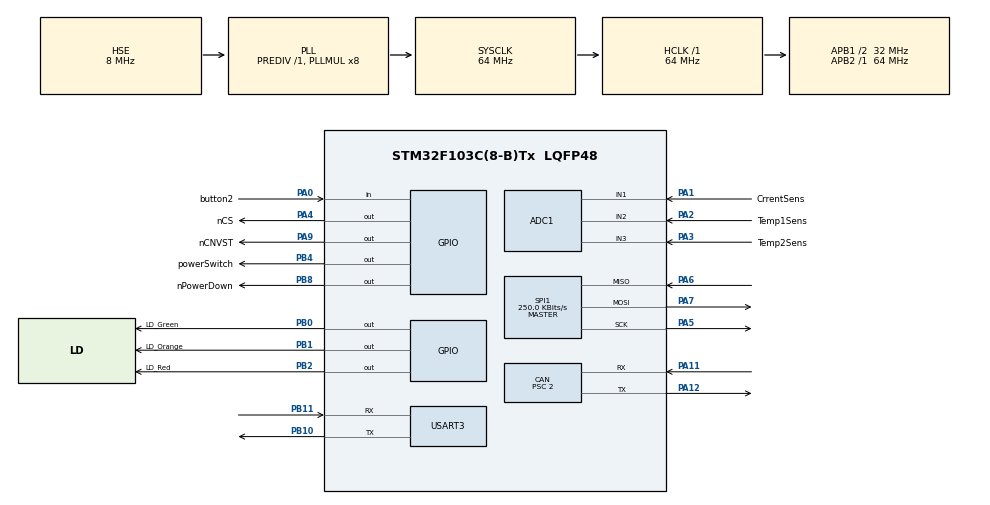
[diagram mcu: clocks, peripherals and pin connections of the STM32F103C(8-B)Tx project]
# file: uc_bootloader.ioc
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ADC1.Channel-0\#ChannelRegularConversion=ADC_CHANNEL_1
ADC1.Channel-1\#ChannelRegularConversion=ADC_CHANNEL_2
ADC1.Channel-2\#ChannelRegularConversion=ADC_CHANNEL_3
ADC1.ContinuousConvMode=DISABLE
ADC1.ExternalTrigConv=ADC_EXTERNALTRIGCONV_T3_TRGO
ADC1.NbrOfConversion=3
ADC1.NbrOfConversionFlag=1
ADC1.Rank-0\#ChannelRegularConversion=1
ADC1.Rank-1\#ChannelRegularConversion=2
ADC1.Rank-2\#ChannelRegularConversion=3
ADC1.SamplingTime-0\#ChannelRegularConversion=ADC_SAMPLETIME_71CYCLES_5
ADC1.SamplingTime-1\#ChannelRegularConversion=ADC_SAMPLETIME_71CYCLES_5
ADC1.SamplingTime-2\#ChannelRegularConversion=ADC_SAMPLETIME_71CYCLES_5
ADC1.master=1
CAN.BS1=CAN_BS1_13TQ
CAN.BS2=CAN_BS2_2TQ
CAN.CalculateBaudRate=1000000
CAN.CalculateTimeBit=1000.00
CAN.CalculateTimeQuantum=62.5
CAN.Prescaler=2
Dma.ADC1.2.Direction=DMA_PERIPH_TO_MEMORY
Dma.ADC1.2.Instance=DMA1_Channel1
Dma.ADC1.2.MemDataAlignment=DMA_MDATAALIGN_HALFWORD
Dma.ADC1.2.MemInc=DMA_MINC_ENABLE
Dma.ADC1.2.Mode=DMA_CIRCULAR
Dma.ADC1.2.PeriphDataAlignment=DMA_PDATAALIGN_HALFWORD
Dma.ADC1.2.PeriphInc=DMA_PINC_DISABLE
Dma.ADC1.2.Priority=DMA_PRIORITY_LOW
Dma.Request0=SPI1_RX
Dma.Request1=SPI1_TX
Dma.Request2=ADC1
Dma.SPI1_RX.0.Direction=DMA_PERIPH_TO_MEMORY
Dma.SPI1_RX.0.Instance=DMA1_Channel2
Dma.SPI1_RX.0.MemDataAlignment=DMA_MDATAALIGN_BYTE
Dma.SPI1_RX.0.MemInc=DMA_MINC_ENABLE
Dma.SPI1_RX.0.Mode=DMA_NORMAL
Dma.SPI1_RX.0.PeriphDataAlignment=DMA_PDATAALIGN_BYTE
Dma.SPI1_RX.0.PeriphInc=DMA_PINC_DISABLE
Dma.SPI1_RX.0.Priority=DMA_PRIORITY_HIGH
Dma.SPI1_TX.1.Direction=DMA_MEMORY_TO_PERIPH
Dma.SPI1_TX.1.Instance=DMA1_Channel3
Dma.SPI1_TX.1.MemDataAlignment=DMA_MDATAALIGN_BYTE
Dma.SPI1_TX.1.MemInc=DMA_MINC_ENABLE
Dma.SPI1_TX.1.Mode=DMA_NORMAL
Dma.SPI1_TX.1.PeriphDataAlignment=DMA_PDATAALIGN_BYTE
Dma.SPI1_TX.1.PeriphInc=DMA_PINC_DISABLE
Dma.SPI1_TX.1.Priority=DMA_PRIORITY_HIGH
Mcu.Family=STM32F1
Mcu.Name=STM32F103C(8-B)Tx
Mcu.Package=LQFP48
NVIC.DMA1_Channel1_IRQn=true\:2\:1\:true\:false\:true\:false\:true
NVIC.DMA1_Channel2_IRQn=true\:2\:0\:true\:false\:true\:false\:true
NVIC.DMA1_Channel3_IRQn=true\:2\:0\:true\:false\:true\:false\:true
NVIC.PriorityGroup=NVIC_PRIORITYGROUP_3
NVIC.TIM1_BRK_IRQn=true\:3\:1\:true\:false\:true\:true\:true
NVIC.TIM1_UP_IRQn=true\:3\:1\:true\:false\:true\:true\:true
NVIC.TIM2_IRQn=true\:1\:0\:true\:false\:true\:true\:true
NVIC.TIM4_IRQn=true\:3\:0\:true\:false\:true\:true\:true
NVIC.USB_HP_CAN1_TX_IRQn=true\:1\:0\:true\:false\:true\:true\:true
NVIC.USB_LP_CAN1_RX0_IRQn=true\:1\:0\:true\:false\:true\:true\:true
PA0-WKUP.GPIO_Label=button2
PA0-WKUP.Signal=GPIO_Input
PA1.GPIO_Label=CrrentSens
PA1.Signal=ADCx_IN1
PA11.Mode=CAN_Activate
PA11.Signal=CAN_RX
PA12.Mode=CAN_Activate
PA12.Signal=CAN_TX
PA13.Mode=Serial_Wire
PA13.Signal=SYS_JTMS-SWDIO
PA14.Mode=Serial_Wire
PA14.Signal=SYS_JTCK-SWCLK
PA2.GPIO_Label=Temp1Sens
PA2.Signal=ADCx_IN2
PA3.GPIO_Label=Temp2Sens
PA3.Signal=ADCx_IN3
PA4.GPIO_Label=nCS
PA4.GPIO_Speed=GPIO_SPEED_FREQ_HIGH
PA4.Signal=GPIO_Output
PA5.Mode=Full_Duplex_Master
PA5.Signal=SPI1_SCK
PA6.Mode=Full_Duplex_Master
PA6.Signal=SPI1_MISO
PA7.Mode=Full_Duplex_Master
PA7.Signal=SPI1_MOSI
PA9.GPIO_Label=nCNVST
PA9.GPIO_Speed=GPIO_SPEED_FREQ_HIGH
PA9.Signal=GPIO_Output
PB0.GPIO_Label=LD_Green
PB0.PinState=GPIO_PIN_RESET
PB0.Signal=GPIO_Output
PB1.GPIO_Label=LD_Orange
PB1.Signal=GPIO_Output
PB10.Mode=Asynchronous
PB10.Signal=USART3_TX
PB11.Mode=Asynchronous
PB11.Signal=USART3_RX
PB2.GPIO_Label=LD_Red
PB2.Signal=GPIO_Output
PB4.GPIO_Label=powerSwitch
PB4.GPIO_Speed=GPIO_SPEED_FREQ_MEDIUM
PB4.Signal=GPIO_Output
PB8.GPIO_Label=nPowerDown
PB8.GPIO_Speed=GPIO_SPEED_FREQ_MEDIUM
PB8.Signal=GPIO_Output
PD0-OSC_IN.Mode=HSE-External-Oscillator
PD0-OSC_IN.Signal=RCC_OSC_IN
PD1-OSC_OUT.Mode=HSE-External-Oscillator
PD1-OSC_OUT.Signal=RCC_OSC_OUT
ProjectManager.HeapSize=0x200
ProjectManager.StackSize=0x400
ProjectManager.TargetToolchain=STM32CubeIDE
RCC.ADCPresc=RCC_ADCPCLK2_DIV8
RCC.AHBFreq_Value=64000000
RCC.APB1CLKDivider=RCC_HCLK_DIV2
RCC.APB1Freq_Value=32000000
RCC.APB1TimFreq_Value=64000000
RCC.APB2Freq_Value=64000000
RCC.APB2TimFreq_Value=64000000
RCC.HCLKFreq_Value=64000000
RCC.PLLMUL=RCC_PLL_MUL8
RCC.PLLSourceVirtual=RCC_PLLSOURCE_HSE
RCC.SYSCLKFreq_VALUE=64000000
RCC.SYSCLKSource=RCC_SYSCLKSOURCE_PLLCLK
RCC.USBFreq_Value=64000000
SH.ADCx_IN1.0=ADC1_IN1,IN1
SH.ADCx_IN2.0=ADC1_IN2,IN2
SH.ADCx_IN3.0=ADC1_IN3,IN3
SPI1.BaudRatePrescaler=SPI_BAUDRATEPRESCALER_256
SPI1.CLKPhase=SPI_PHASE_2EDGE
SPI1.CalculateBaudRate=250.0 KBits/s
SPI1.Direction=SPI_DIRECTION_2LINES
SPI1.Mode=SPI_MODE_MASTER
SPI1.VirtualType=VM_MASTER
TIM1.Period=30
TIM1.Prescaler=63999
TIM2.Period=100
TIM2.Prescaler=63999
TIM3.Period=10
TIM3.Prescaler=63999
TIM3.TIM_MasterOutputTrigger=TIM_TRGO_UPDATE
TIM4.Period=60
TIM4.Prescaler=63999
USART3.VirtualMode=VM_ASYNC
VP_TIM1_VS_ClockSourceINT.Mode=Internal
VP_TIM2_VS_ClockSourceINT.Mode=Internal
VP_TIM3_VS_ClockSourceINT.Mode=Internal
VP_TIM4_VS_ClockSourceINT.Mode=Internal
board=custom

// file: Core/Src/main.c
/* USER CODE BEGIN Header */
/**
  ******************************************************************************
  * @file           : main.c
  * @brief          : Main program body
  ******************************************************************************
  * @attention
  *
  * <h2><center>&copy; Copyright (c) 2021 STMicroelectronics.
  * All rights reserved.</center></h2>
  *
  * This software component is licensed by ST under BSD 3-Clause license,
  * the "License"; You may not use this file except in compliance with the
  * License. You may obtain a copy of the License at:
  *                        opensource.org/licenses/BSD-3-Clause
  *
  ******************************************************************************
  */
/* USER CODE END Header */
#include "main.h"
#include "boot_ctrl.h"
#include "can.h"
#include "flash_memory.h"
#include "timers.h"

ADC_HandleTypeDef hadc1;
DMA_HandleTypeDef hdma_adc1;

CAN_HandleTypeDef hcan;

SPI_HandleTypeDef hspi1;
DMA_HandleTypeDef hdma_spi1_rx;
DMA_HandleTypeDef hdma_spi1_tx;

TIM_HandleTypeDef htim1;
TIM_HandleTypeDef htim2;
TIM_HandleTypeDef htim3;
TIM_HandleTypeDef htim4;

UART_HandleTypeDef huart3;

void SystemClock_Config(void);
static void MX_GPIO_Init(void);
static void MX_DMA_Init(void);
static void MX_ADC1_Init(void);
static void MX_CAN_Init(void);
static void MX_SPI1_Init(void);
static void MX_TIM1_Init(void);
static void MX_TIM2_Init(void);
static void MX_TIM3_Init(void);
static void MX_TIM4_Init(void);
static void MX_USART3_UART_Init(void);

int main(void)
{
	// Flag = 0 --> Jump to App
	// Flag = 1 --> Bootloader Mode
	// Check if app mode is enabled. If yes, jump to app
	if(is_app_mode())
		jump_boot_to_app();

	/* Reset of all peripherals, Initializes the Flash interface and the Systick. */
	HAL_Init();

	/* Configure the system clock */
	SystemClock_Config();

	/* Initialize all configured peripherals */
	MX_GPIO_Init();
	MX_DMA_Init();
	MX_ADC1_Init();
	MX_CAN_Init();
	MX_SPI1_Init();
	MX_TIM1_Init();
	MX_TIM2_Init();
	MX_TIM3_Init();
	MX_TIM4_Init();
	MX_USART3_UART_Init();

	boot_init();

	while (1)
	{
		// CAN bus reception and transmission
		can_core_rx();
		can_core_tx();
		// Bootloader core
		boot_core();
	}
}

void SystemClock_Config(void)
{
  RCC_OscInitTypeDef RCC_OscInitStruct = {0};
  RCC_ClkInitTypeDef RCC_ClkInitStruct = {0};
  RCC_PeriphCLKInitTypeDef PeriphClkInit = {0};

  /** Initializes the RCC Oscillators according to the specified parameters
  * in the RCC_OscInitTypeDef structure.
  */
  RCC_OscInitStruct.OscillatorType = RCC_OSCILLATORTYPE_HSE;
  RCC_OscInitStruct.HSEState = RCC_HSE_ON;
  RCC_OscInitStruct.HSEPredivValue = RCC_HSE_PREDIV_DIV1;
  RCC_OscInitStruct.HSIState = RCC_HSI_ON;
  RCC_OscInitStruct.PLL.PLLState = RCC_PLL_ON;
  RCC_OscInitStruct.PLL.PLLSource = RCC_PLLSOURCE_HSE;
  RCC_OscInitStruct.PLL.PLLMUL = RCC_PLL_MUL8;
  if (HAL_RCC_OscConfig(&RCC_OscInitStruct) != HAL_OK)
  {
    Error_Handler();
  }
  /** Initializes the CPU, AHB and APB buses clocks
  */
  RCC_ClkInitStruct.ClockType = RCC_CLOCKTYPE_HCLK|RCC_CLOCKTYPE_SYSCLK
                              |RCC_CLOCKTYPE_PCLK1|RCC_CLOCKTYPE_PCLK2;
  RCC_ClkInitStruct.SYSCLKSource = RCC_SYSCLKSOURCE_PLLCLK;
  RCC_ClkInitStruct.AHBCLKDivider = RCC_SYSCLK_DIV1;
  RCC_ClkInitStruct.APB1CLKDivider = RCC_HCLK_DIV2;
  RCC_ClkInitStruct.APB2CLKDivider = RCC_HCLK_DIV1;

  if (HAL_RCC_ClockConfig(&RCC_ClkInitStruct, FLASH_LATENCY_2) != HAL_OK)
  {
    Error_Handler();
  }
  PeriphClkInit.PeriphClockSelection = RCC_PERIPHCLK_ADC;
  PeriphClkInit.AdcClockSelection = RCC_ADCPCLK2_DIV8;
  if (HAL_RCCEx_PeriphCLKConfig(&PeriphClkInit) != HAL_OK)
  {
    Error_Handler();
  }
}

static void MX_ADC1_Init(void)
{

  ADC_ChannelConfTypeDef sConfig = {0};

  /** Common config
  */
  hadc1.Instance = ADC1;
  hadc1.Init.ScanConvMode = ADC_SCAN_ENABLE;
  hadc1.Init.ContinuousConvMode = DISABLE;
  hadc1.Init.DiscontinuousConvMode = DISABLE;
  hadc1.Init.ExternalTrigConv = ADC_EXTERNALTRIGCONV_T3_TRGO;
  hadc1.Init.DataAlign = ADC_DATAALIGN_RIGHT;
  hadc1.Init.NbrOfConversion = 3;
  if (HAL_ADC_Init(&hadc1) != HAL_OK)
  {
    Error_Handler();
  }
  /** Configure Regular Channel
  */
  sConfig.Channel = ADC_CHANNEL_1;
  sConfig.Rank = ADC_REGULAR_RANK_1;
  sConfig.SamplingTime = ADC_SAMPLETIME_71CYCLES_5;
  if (HAL_ADC_ConfigChannel(&hadc1, &sConfig) != HAL_OK)
  {
    Error_Handler();
  }
  /** Configure Regular Channel
  */
  sConfig.Channel = ADC_CHANNEL_2;
  sConfig.Rank = ADC_REGULAR_RANK_2;
  if (HAL_ADC_ConfigChannel(&hadc1, &sConfig) != HAL_OK)
  {
    Error_Handler();
  }
  /** Configure Regular Channel
  */
  sConfig.Channel = ADC_CHANNEL_3;
  sConfig.Rank = ADC_REGULAR_RANK_3;
  if (HAL_ADC_ConfigChannel(&hadc1, &sConfig) != HAL_OK)
  {
    Error_Handler();
  }

}

static void MX_CAN_Init(void)
{

  /* USER CODE BEGIN CAN_Init 0 */
//	CAN_FilterTypeDef sFilterConfig_0, sFilterConfig_1, sFilterConfig_2;
  /* USER CODE END CAN_Init 0 */

  hcan.Instance = CAN1;
  hcan.Init.Prescaler = 2;
  hcan.Init.Mode = CAN_MODE_NORMAL;
  hcan.Init.SyncJumpWidth = CAN_SJW_1TQ;
  hcan.Init.TimeSeg1 = CAN_BS1_13TQ;
  hcan.Init.TimeSeg2 = CAN_BS2_2TQ;
  hcan.Init.TimeTriggeredMode = DISABLE;
  hcan.Init.AutoBusOff = DISABLE;
  hcan.Init.AutoWakeUp = DISABLE;
  hcan.Init.AutoRetransmission = DISABLE;
  hcan.Init.ReceiveFifoLocked = DISABLE;
  hcan.Init.TransmitFifoPriority = DISABLE;
  if (HAL_CAN_Init(&hcan) != HAL_OK)
  {
    Error_Handler();
  }
  /* USER CODE BEGIN CAN_Init 2 */
	CAN_FilterTypeDef sf;

	sf.FilterBank = 0;
	sf.FilterMode = CAN_FILTERMODE_IDMASK;
	sf.FilterScale = CAN_FILTERSCALE_32BIT;
	sf.FilterIdLow = 0x600;
	sf.FilterIdHigh = 0x6ff;
	sf.FilterMaskIdLow = 0x0000;
	sf.FilterMaskIdHigh = 0x0000;
	sf.FilterFIFOAssignment = CAN_RX_FIFO0;
	sf.SlaveStartFilterBank = 0;
	sf.FilterActivation = ENABLE;
	if (HAL_CAN_ConfigFilter(&hcan, &sf) != HAL_OK) {
		Error_Handler();
	}
  /* USER CODE END CAN_Init 2 */

}

static void MX_SPI1_Init(void)
{

  /* SPI1 parameter configuration*/
  hspi1.Instance = SPI1;
  hspi1.Init.Mode = SPI_MODE_MASTER;
  hspi1.Init.Direction = SPI_DIRECTION_2LINES;
  hspi1.Init.DataSize = SPI_DATASIZE_8BIT;
  hspi1.Init.CLKPolarity = SPI_POLARITY_LOW;
  hspi1.Init.CLKPhase = SPI_PHASE_2EDGE;
  hspi1.Init.NSS = SPI_NSS_SOFT;
  hspi1.Init.BaudRatePrescaler = SPI_BAUDRATEPRESCALER_256;
  hspi1.Init.FirstBit = SPI_FIRSTBIT_MSB;
  hspi1.Init.TIMode = SPI_TIMODE_DISABLE;
  hspi1.Init.CRCCalculation = SPI_CRCCALCULATION_DISABLE;
  hspi1.Init.CRCPolynomial = 10;
  if (HAL_SPI_Init(&hspi1) != HAL_OK)
  {
    Error_Handler();
  }

}

static void MX_TIM1_Init(void)
{

  TIM_ClockConfigTypeDef sClockSourceConfig = {0};
  TIM_MasterConfigTypeDef sMasterConfig = {0};

  htim1.Instance = TIM1;
  htim1.Init.Prescaler = 63999;
  htim1.Init.CounterMode = TIM_COUNTERMODE_UP;
  htim1.Init.Period = 30;
  htim1.Init.ClockDivision = TIM_CLOCKDIVISION_DIV1;
  htim1.Init.RepetitionCounter = 0;
  htim1.Init.AutoReloadPreload = TIM_AUTORELOAD_PRELOAD_DISABLE;
  if (HAL_TIM_Base_Init(&htim1) != HAL_OK)
  {
    Error_Handler();
  }
  sClockSourceConfig.ClockSource = TIM_CLOCKSOURCE_INTERNAL;
  if (HAL_TIM_ConfigClockSource(&htim1, &sClockSourceConfig) != HAL_OK)
  {
    Error_Handler();
  }
  sMasterConfig.MasterOutputTrigger = TIM_TRGO_RESET;
  sMasterConfig.MasterSlaveMode = TIM_MASTERSLAVEMODE_DISABLE;
  if (HAL_TIMEx_MasterConfigSynchronization(&htim1, &sMasterConfig) != HAL_OK)
  {
    Error_Handler();
  }

}

static void MX_TIM2_Init(void)
{

  TIM_ClockConfigTypeDef sClockSourceConfig = {0};
  TIM_MasterConfigTypeDef sMasterConfig = {0};

  htim2.Instance = TIM2;
  htim2.Init.Prescaler = 639;
  htim2.Init.CounterMode = TIM_COUNTERMODE_UP;
  htim2.Init.Period = 100;
  htim2.Init.ClockDivision = TIM_CLOCKDIVISION_DIV1;
  htim2.Init.AutoReloadPreload = TIM_AUTORELOAD_PRELOAD_DISABLE;
  if (HAL_TIM_Base_Init(&htim2) != HAL_OK)
  {
    Error_Handler();
  }
  sClockSourceConfig.ClockSource = TIM_CLOCKSOURCE_INTERNAL;
  if (HAL_TIM_ConfigClockSource(&htim2, &sClockSourceConfig) != HAL_OK)
  {
    Error_Handler();
  }
  sMasterConfig.MasterOutputTrigger = TIM_TRGO_RESET;
  sMasterConfig.MasterSlaveMode = TIM_MASTERSLAVEMODE_DISABLE;
  if (HAL_TIMEx_MasterConfigSynchronization(&htim2, &sMasterConfig) != HAL_OK)
  {
    Error_Handler();
  }

}

static void MX_TIM3_Init(void)
{

  TIM_ClockConfigTypeDef sClockSourceConfig = {0};
  TIM_MasterConfigTypeDef sMasterConfig = {0};

  htim3.Instance = TIM3;
  htim3.Init.Prescaler = 63999;
  htim3.Init.CounterMode = TIM_COUNTERMODE_UP;
  htim3.Init.Period = 10;
  htim3.Init.ClockDivision = TIM_CLOCKDIVISION_DIV1;
  htim3.Init.AutoReloadPreload = TIM_AUTORELOAD_PRELOAD_DISABLE;
  if (HAL_TIM_Base_Init(&htim3) != HAL_OK)
  {
    Error_Handler();
  }
  sClockSourceConfig.ClockSource = TIM_CLOCKSOURCE_INTERNAL;
  if (HAL_TIM_ConfigClockSource(&htim3, &sClockSourceConfig) != HAL_OK)
  {
    Error_Handler();
  }
  sMasterConfig.MasterOutputTrigger = TIM_TRGO_UPDATE;
  sMasterConfig.MasterSlaveMode = TIM_MASTERSLAVEMODE_DISABLE;
  if (HAL_TIMEx_MasterConfigSynchronization(&htim3, &sMasterConfig) != HAL_OK)
  {
    Error_Handler();
  }

}

static void MX_TIM4_Init(void)
{

  TIM_ClockConfigTypeDef sClockSourceConfig = {0};
  TIM_MasterConfigTypeDef sMasterConfig = {0};

  htim4.Instance = TIM4;
  htim4.Init.Prescaler = 63999;
  htim4.Init.CounterMode = TIM_COUNTERMODE_UP;
  htim4.Init.Period = 60;
  htim4.Init.ClockDivision = TIM_CLOCKDIVISION_DIV1;
  htim4.Init.AutoReloadPreload = TIM_AUTORELOAD_PRELOAD_DISABLE;
  if (HAL_TIM_Base_Init(&htim4) != HAL_OK)
  {
    Error_Handler();
  }
  sClockSourceConfig.ClockSource = TIM_CLOCKSOURCE_INTERNAL;
  if (HAL_TIM_ConfigClockSource(&htim4, &sClockSourceConfig) != HAL_OK)
  {
    Error_Handler();
  }
  sMasterConfig.MasterOutputTrigger = TIM_TRGO_RESET;
  sMasterConfig.MasterSlaveMode = TIM_MASTERSLAVEMODE_DISABLE;
  if (HAL_TIMEx_MasterConfigSynchronization(&htim4, &sMasterConfig) != HAL_OK)
  {
    Error_Handler();
  }

}

static void MX_USART3_UART_Init(void)
{

  huart3.Instance = USART3;
  huart3.Init.BaudRate = 115200;
  huart3.Init.WordLength = UART_WORDLENGTH_8B;
  huart3.Init.StopBits = UART_STOPBITS_1;
  huart3.Init.Parity = UART_PARITY_NONE;
  huart3.Init.Mode = UART_MODE_TX_RX;
  huart3.Init.HwFlowCtl = UART_HWCONTROL_NONE;
  huart3.Init.OverSampling = UART_OVERSAMPLING_16;
  if (HAL_UART_Init(&huart3) != HAL_OK)
  {
    Error_Handler();
  }

}

static void MX_DMA_Init(void)
{

  /* DMA controller clock enable */
  __HAL_RCC_DMA1_CLK_ENABLE();

  /* DMA interrupt init */
  /* DMA1_Channel1_IRQn interrupt configuration */
  HAL_NVIC_SetPriority(DMA1_Channel1_IRQn, 2, 1);
  HAL_NVIC_EnableIRQ(DMA1_Channel1_IRQn);
  /* DMA1_Channel2_IRQn interrupt configuration */
  HAL_NVIC_SetPriority(DMA1_Channel2_IRQn, 2, 0);
  HAL_NVIC_EnableIRQ(DMA1_Channel2_IRQn);
  /* DMA1_Channel3_IRQn interrupt configuration */
  HAL_NVIC_SetPriority(DMA1_Channel3_IRQn, 2, 0);
  HAL_NVIC_EnableIRQ(DMA1_Channel3_IRQn);

}

static void MX_GPIO_Init(void)
{
  GPIO_InitTypeDef GPIO_InitStruct = {0};

  /* GPIO Ports Clock Enable */
  __HAL_RCC_GPIOD_CLK_ENABLE();
  __HAL_RCC_GPIOA_CLK_ENABLE();
  __HAL_RCC_GPIOB_CLK_ENABLE();

  /*Configure GPIO pin Output Level */
  HAL_GPIO_WritePin(GPIOA, nCS_Pin|nCNVST_Pin, GPIO_PIN_RESET);

  /*Configure GPIO pin Output Level */
  HAL_GPIO_WritePin(GPIOB, LD_Green_Pin|LD_Orange_Pin|LD_Red_Pin|powerSwitch_Pin
                          |nPowerDown_Pin, GPIO_PIN_RESET);

  /*Configure GPIO pin : button2_Pin */
  GPIO_InitStruct.Pin = button2_Pin;
  GPIO_InitStruct.Mode = GPIO_MODE_INPUT;
  GPIO_InitStruct.Pull = GPIO_NOPULL;
  HAL_GPIO_Init(button2_GPIO_Port, &GPIO_InitStruct);

  /*Configure GPIO pins : nCS_Pin nCNVST_Pin */
  GPIO_InitStruct.Pin = nCS_Pin|nCNVST_Pin;
  GPIO_InitStruct.Mode = GPIO_MODE_OUTPUT_PP;
  GPIO_InitStruct.Pull = GPIO_NOPULL;
  GPIO_InitStruct.Speed = GPIO_SPEED_FREQ_HIGH;
  HAL_GPIO_Init(GPIOA, &GPIO_InitStruct);

  /*Configure GPIO pins : LD_Green_Pin LD_Orange_Pin LD_Red_Pin */
  GPIO_InitStruct.Pin = LD_Green_Pin|LD_Orange_Pin|LD_Red_Pin;
  GPIO_InitStruct.Mode = GPIO_MODE_OUTPUT_PP;
  GPIO_InitStruct.Pull = GPIO_NOPULL;
  GPIO_InitStruct.Speed = GPIO_SPEED_FREQ_LOW;
  HAL_GPIO_Init(GPIOB, &GPIO_InitStruct);

  /*Configure GPIO pins : powerSwitch_Pin nPowerDown_Pin */
  GPIO_InitStruct.Pin = powerSwitch_Pin|nPowerDown_Pin;
  GPIO_InitStruct.Mode = GPIO_MODE_OUTPUT_PP;
  GPIO_InitStruct.Pull = GPIO_NOPULL;
  GPIO_InitStruct.Speed = GPIO_SPEED_FREQ_MEDIUM;
  HAL_GPIO_Init(GPIOB, &GPIO_InitStruct);

}

void Error_Handler(void)
{
  __disable_irq();
  while (1)
  {
  }
}

/************************ (C) COPYRIGHT STMicroelectronics *****END OF FILE****/
